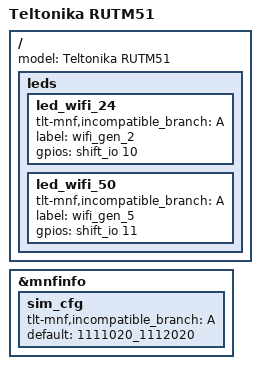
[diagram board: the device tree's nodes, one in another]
#include "common-mt7621/rutm.dtsi"
#include "common-mt7621/input-output.dtsi"
#include "common-mt7621/shiftreg.dtsi"
#include "common-mt7621/eth/4-lan-ports.dtsi"
#include "common-mt7621/leds/wan.dtsi"
#include "common-mt7621/leds/wifi.dtsi"
#include "common-mt7621/modem/5g.dtsi"
#include "mt7621-teltonika-rutm51a.dtsi"

// PWR, RST |G0|G10|
// IN, OUT  |G8|G12|
// SR CTRL  |G5|G9|G11|G44|
// WAN      |G41-G43|G45|
// WIFI     |S10|S11|
// ETH      |S0-S9|
// 5G		|G13-G17|G46-G48|
/ {
	model = "Teltonika RUTM51";

	leds {
		led_wifi_24 {
			tlt-mnf,incompatible_branch = "A";
			label = "wifi_gen_2";
			gpios = <&shift_io 10 GPIO_ACTIVE_HIGH>;
		};

		led_wifi_50 {
			tlt-mnf,incompatible_branch = "A";
			label = "wifi_gen_5";
			gpios = <&shift_io 11 GPIO_ACTIVE_HIGH>;
		};

	};
};

&mnfinfo {

	sim_cfg {
		tlt-mnf,incompatible_branch = "A";
		default = "1111020_1112020";
	};

};
